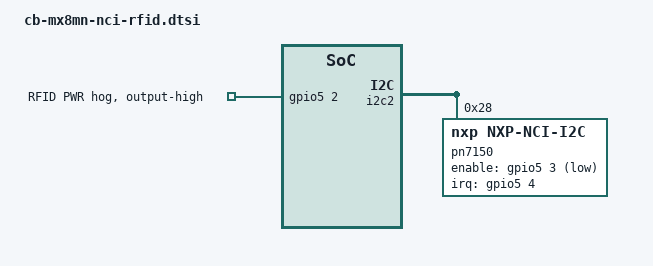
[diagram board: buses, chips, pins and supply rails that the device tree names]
&i2c2 {
        pn7150: pn7150@28 {
                compatible = "nxp,nxp-nci-i2c";
                reg = <0x28>;
                pinctrl-names = "default";
                pinctrl-0 = <&pinctrl_nci_nfc>;
                interrupt-parent = <&gpio5>;
                interrupts = <4 IRQ_TYPE_LEVEL_HIGH>;
                enable-gpios = <&gpio5 3 GPIO_ACTIVE_LOW>;

        };
};

&iomuxc {
    imx8mn-evk {
        pinctrl_nci_nfc: nci_nfcgrp {
            fsl,pins = <

                MX8MN_IOMUXC_SPDIF_TX_GPIO5_IO3 0x0 /* ENABLE OFF */
                MX8MN_IOMUXC_SPDIF_RX_GPIO5_IO4 0x0 /* INT (active on low level) Achtung: muss im Treiber angepasst werden */
            >;
        };
    };
};

&gpio5 {
	RFID {
		status = "okay";
		gpio-hog;
		gpios = <2 0>;
		output-high;
		line-name = "RFID PWR";
	};
};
